# Espressif register map
File version: 1.0
CPU: Xtensa LX6 1, little endian, no MPU, FPU, 3 interrupt priority bits
Registers are 32-bit, access not given, reset 0x0 unless marked. A register's access mark holds for its fields unless they carry their own. Offsets are from the block's base; [hi:lo] are bit positions; {n}, {i} and the like mark numbered series.

## HINF
Base 0x3FF4B000
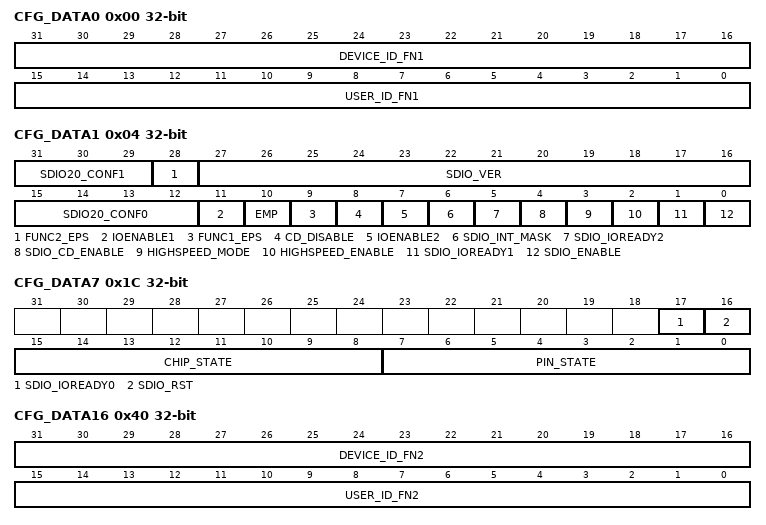
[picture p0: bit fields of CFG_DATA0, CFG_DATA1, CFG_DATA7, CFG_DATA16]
0x00 CFG_DATA0 — HINF_CFG_DATA0
  [31:16] DEVICE_ID_FN1, [15:0] USER_ID_FN1
0x04 CFG_DATA1 — HINF_CFG_DATA1
  [31:29] SDIO20_CONF1, [28] FUNC2_EPS, [27:16] SDIO_VER, [15:12] SDIO20_CONF0, [11] IOENABLE1, [10] EMP, [9] FUNC1_EPS, [8] CD_DISABLE, [7] IOENABLE2, [6] SDIO_INT_MASK, [5] SDIO_IOREADY2, [4] SDIO_CD_ENABLE, [3] HIGHSPEED_MODE, [2] HIGHSPEED_ENABLE, [1] SDIO_IOREADY1, [0] SDIO_ENABLE
0x1C CFG_DATA7 — HINF_CFG_DATA7
  [17] SDIO_IOREADY0, [16] SDIO_RST, [15:8] CHIP_STATE, [7:0] PIN_STATE
{0x20+4i} CIS_CONF{i} (i=0..7) — HINF_CIS_CONF{i}
  [31:0] CIS_CONF_W{i}
0x40 CFG_DATA16 — HINF_CFG_DATA16
  [31:16] DEVICE_ID_FN2, [15:0] USER_ID_FN2
0xFC DATE — HINF_DATE
  [31:0] SDIO_DATE

## I2C
Base 0x00000000
0x00 SCL_LOW_PERIOD — I2C_SCL_LOW_PERIOD
  [13:0] SCL_LOW_PERIOD
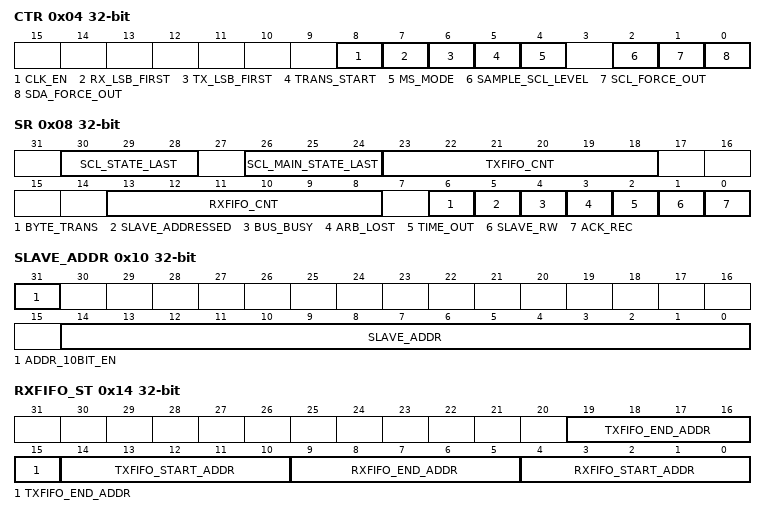
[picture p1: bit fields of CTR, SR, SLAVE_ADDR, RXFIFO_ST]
0x04 CTR — I2C_CTR
  [8] CLK_EN, [7] RX_LSB_FIRST, [6] TX_LSB_FIRST, [5] TRANS_START, [4] MS_MODE, [2] SAMPLE_SCL_LEVEL, [1] SCL_FORCE_OUT, [0] SDA_FORCE_OUT
0x08 SR — I2C_SR
  [30:28] SCL_STATE_LAST, [26:24] SCL_MAIN_STATE_LAST, [23:18] TXFIFO_CNT, [13:8] RXFIFO_CNT, [6] BYTE_TRANS, [5] SLAVE_ADDRESSED, [4] BUS_BUSY, [3] ARB_LOST, [2] TIME_OUT, [1] SLAVE_RW, [0] ACK_REC
0x0C TO — I2C_TO
  [19:0] TIME_OUT_REG
0x10 SLAVE_ADDR — I2C_SLAVE_ADDR
  [31] ADDR_10BIT_EN, [14:0] SLAVE_ADDR
0x14 RXFIFO_ST — I2C_RXFIFO_ST
  [19:15] TXFIFO_END_ADDR, [14:10] TXFIFO_START_ADDR, [9:5] RXFIFO_END_ADDR, [4:0] RXFIFO_START_ADDR
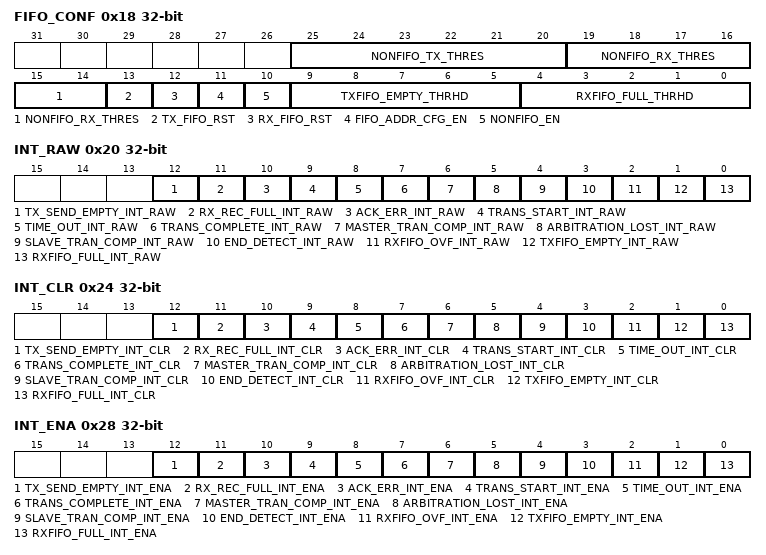
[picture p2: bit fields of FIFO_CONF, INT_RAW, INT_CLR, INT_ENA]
0x18 FIFO_CONF — I2C_FIFO_CONF
  [25:20] NONFIFO_TX_THRES, [19:14] NONFIFO_RX_THRES, [13] TX_FIFO_RST, [12] RX_FIFO_RST, [11] FIFO_ADDR_CFG_EN, [10] NONFIFO_EN, [9:5] TXFIFO_EMPTY_THRHD, [4:0] RXFIFO_FULL_THRHD
0x1C DATA — I2C_DATA
  [7:0] FIFO_RDATA
0x20 INT_RAW — I2C_INT_RAW
  [12] TX_SEND_EMPTY_INT_RAW, [11] RX_REC_FULL_INT_RAW, [10] ACK_ERR_INT_RAW, [9] TRANS_START_INT_RAW, [8] TIME_OUT_INT_RAW, [7] TRANS_COMPLETE_INT_RAW, [6] MASTER_TRAN_COMP_INT_RAW, [5] ARBITRATION_LOST_INT_RAW, [4] SLAVE_TRAN_COMP_INT_RAW, [3] END_DETECT_INT_RAW, [2] RXFIFO_OVF_INT_RAW, [1] TXFIFO_EMPTY_INT_RAW, [0] RXFIFO_FULL_INT_RAW
0x24 INT_CLR — I2C_INT_CLR
  [12] TX_SEND_EMPTY_INT_CLR, [11] RX_REC_FULL_INT_CLR, [10] ACK_ERR_INT_CLR, [9] TRANS_START_INT_CLR, [8] TIME_OUT_INT_CLR, [7] TRANS_COMPLETE_INT_CLR, [6] MASTER_TRAN_COMP_INT_CLR, [5] ARBITRATION_LOST_INT_CLR, [4] SLAVE_TRAN_COMP_INT_CLR, [3] END_DETECT_INT_CLR, [2] RXFIFO_OVF_INT_CLR, [1] TXFIFO_EMPTY_INT_CLR, [0] RXFIFO_FULL_INT_CLR
0x28 INT_ENA — I2C_INT_ENA
  [12] TX_SEND_EMPTY_INT_ENA, [11] RX_REC_FULL_INT_ENA, [10] ACK_ERR_INT_ENA, [9] TRANS_START_INT_ENA, [8] TIME_OUT_INT_ENA, [7] TRANS_COMPLETE_INT_ENA, [6] MASTER_TRAN_COMP_INT_ENA, [5] ARBITRATION_LOST_INT_ENA, [4] SLAVE_TRAN_COMP_INT_ENA, [3] END_DETECT_INT_ENA, [2] RXFIFO_OVF_INT_ENA, [1] TXFIFO_EMPTY_INT_ENA, [0] RXFIFO_FULL_INT_ENA
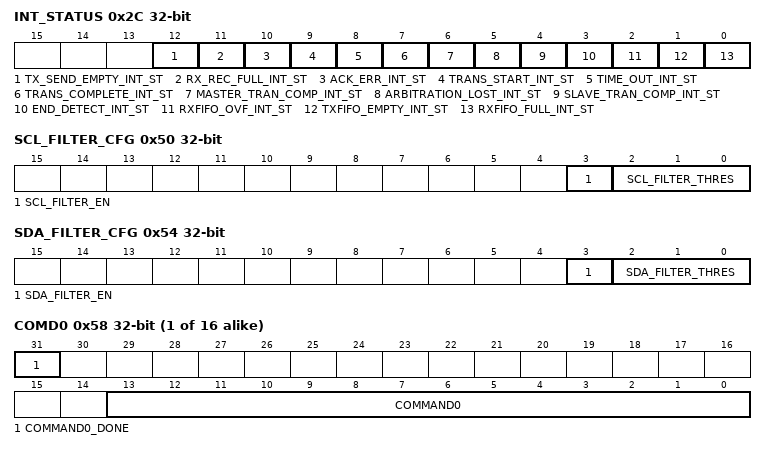
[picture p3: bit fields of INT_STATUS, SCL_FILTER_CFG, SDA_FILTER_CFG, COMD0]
0x2C INT_STATUS — I2C_INT_STATUS
  [12] TX_SEND_EMPTY_INT_ST, [11] RX_REC_FULL_INT_ST, [10] ACK_ERR_INT_ST, [9] TRANS_START_INT_ST, [8] TIME_OUT_INT_ST, [7] TRANS_COMPLETE_INT_ST, [6] MASTER_TRAN_COMP_INT_ST, [5] ARBITRATION_LOST_INT_ST, [4] SLAVE_TRAN_COMP_INT_ST, [3] END_DETECT_INT_ST, [2] RXFIFO_OVF_INT_ST, [1] TXFIFO_EMPTY_INT_ST, [0] RXFIFO_FULL_INT_ST
0x30 SDA_HOLD — I2C_SDA_HOLD
  [9:0] SDA_HOLD_TIME
0x34 SDA_SAMPLE — I2C_SDA_SAMPLE
  [9:0] SDA_SAMPLE_TIME
0x38 SCL_HIGH_PERIOD — I2C_SCL_HIGH_PERIOD
  [13:0] SCL_HIGH_PERIOD
0x40 SCL_START_HOLD — I2C_SCL_START_HOLD
  [9:0] SCL_START_HOLD_TIME
0x44 SCL_RSTART_SETUP — I2C_SCL_RSTART_SETUP
  [9:0] SCL_RSTART_SETUP_TIME
0x48 SCL_STOP_HOLD — I2C_SCL_STOP_HOLD
  [13:0] SCL_STOP_HOLD_TIME
0x4C SCL_STOP_SETUP — I2C_SCL_STOP_SETUP
  [9:0] SCL_STOP_SETUP_TIME
0x50 SCL_FILTER_CFG — I2C_SCL_FILTER_CFG
  [3] SCL_FILTER_EN, [2:0] SCL_FILTER_THRES
0x54 SDA_FILTER_CFG — I2C_SDA_FILTER_CFG
  [3] SDA_FILTER_EN, [2:0] SDA_FILTER_THRES
{0x58+4i} COMD{i} (i=0..15) — I2C_COMD{i}
  [31] COMMAND{i}_DONE, [13:0] COMMAND{i}
0xF8 DATE — I2C_DATE
